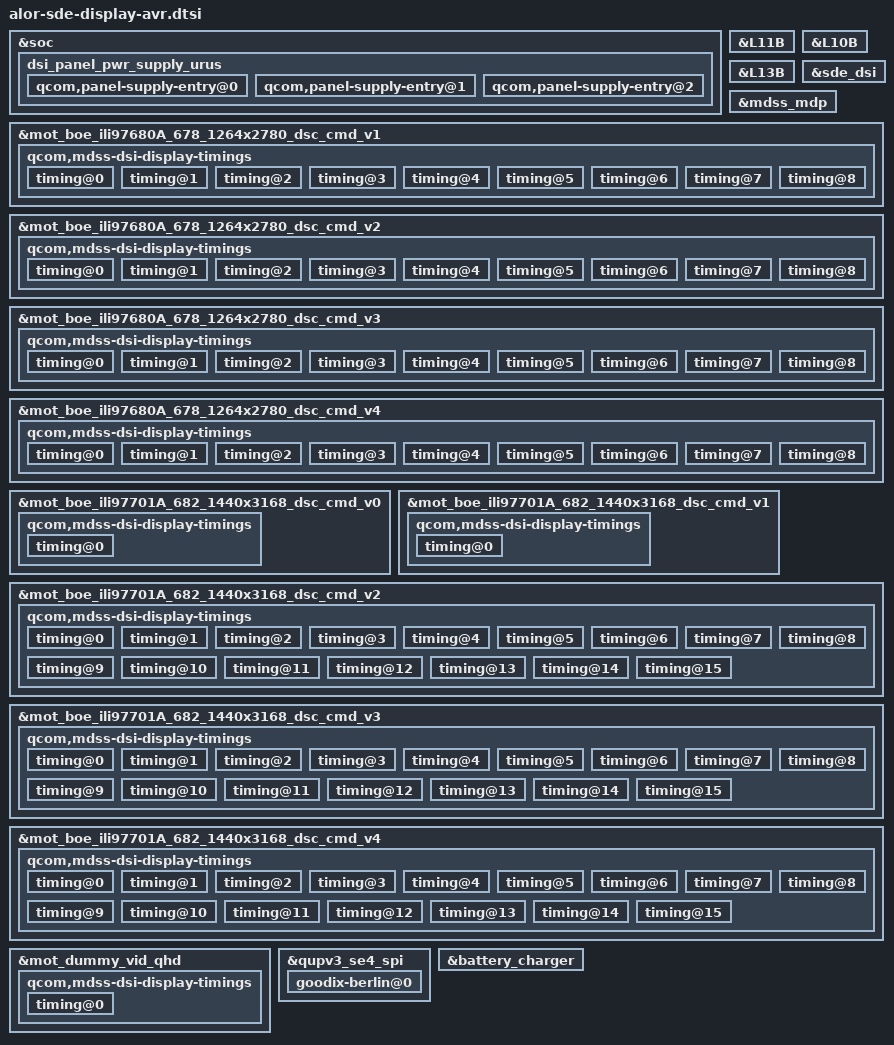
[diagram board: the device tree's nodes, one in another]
// SPDX-License-Identifier: BSD-3-Clause
/*
 * Copyright (c) Qualcomm Technologies, Inc. and/or its subsidiaries.
 */

#include "alor-sde-display.dtsi"
#include "dsi-panel-mot-dummy-qhd-video-dsi1.dtsi"
#include "dsi-panel-mot-boe-ili97680A-678-1264x2780-dsc-cmd-common_vantage_v1.dtsi"
#include "dsi-panel-mot-boe-ili97680A-678-1264x2780-dsc-cmd-common_vantage_v2.dtsi"
#include "dsi-panel-mot-boe-ili97680A-678-1264x2780-dsc-cmd-common_vantage_v3.dtsi"
#include "dsi-panel-mot-boe-ili97680A-678-1264x2780-dsc-cmd-common_vantage_v4.dtsi"
#include "dsi-panel-mot-boe-ili97701A-682-1440x3168-dsc-cmd-common_v0.dtsi"
#include "dsi-panel-mot-boe-ili97701A-682-1440x3168-dsc-cmd-common_v1.dtsi"
#include "dsi-panel-mot-boe-ili97701A-682-1440x3168-dsc-cmd-common_v2.dtsi"
#include "dsi-panel-mot-boe-ili97701A-682-1440x3168-dsc-cmd-common_v3.dtsi"
#include "dsi-panel-mot-boe-ili97701A-682-1440x3168-dsc-cmd-common_v4.dtsi"
&soc {
	dsi_panel_pwr_supply_urus: dsi_panel_pwr_supply_urus {
		#address-cells = <1>;
		#size-cells = <0>;

	qcom,panel-supply-entry@0 {
		reg = <0>;
		qcom,supply-name = "vddio";
		qcom,supply-min-voltage = <1850000>;
		qcom,supply-max-voltage = <1850000>;
		qcom,supply-enable-load = <300000>;
		qcom,supply-disable-load = <100>;
		qcom,supply-pre-on-sleep = <0>;
		qcom,supply-post-on-sleep = <1>;
		qcom,supply-pre-off-sleep = <0>;
		qcom,supply-post-off-sleep = <0>;
        };
	qcom,panel-supply-entry@1 {
		reg = <1>;
		qcom,supply-name = "vdd";
		qcom,supply-min-voltage = <1060000>;
		qcom,supply-max-voltage = <1060000>;
		qcom,supply-enable-load = <300000>;
		qcom,supply-disable-load = <100>;
		qcom,supply-pre-on-sleep = <0>;
		qcom,supply-post-on-sleep = <1>;
		qcom,supply-pre-off-sleep = <0>;
		qcom,supply-post-off-sleep = <1>;
        };

        qcom,panel-supply-entry@2 {
		reg = <2>;
		qcom,supply-name = "vci";
		qcom,supply-min-voltage = <3000000>;
		qcom,supply-max-voltage = <3000000>;
		qcom,supply-enable-load = <3000000>;
		qcom,supply-disable-load = <0>;
		qcom,supply-pre-on-sleep = <0>;
		qcom,supply-post-on-sleep = <0>;
		qcom,supply-pre-off-sleep = <1>;
		qcom,supply-post-off-sleep = <1>;
        };
	};
};
&L11B {
       regulator-min-microvolt = <1060000>;
       regulator-max-microvolt = <1060000>;
       qcom,init-voltage = <1060000>;
};
&L10B {
       regulator-min-microvolt = <1850000>;
       regulator-max-microvolt = <1850000>;
       qcom,init-voltage = <1850000>;
};
&L13B {
       regulator-min-microvolt = <3000000>;
       regulator-max-microvolt = <3000000>;
       qcom,init-voltage = <3000000>;
};

&sde_dsi {
	pinctrl-names = "panel_active", "panel_suspend";
	pinctrl-0 = <&sde_dsi_active &sde_te_active>;
	pinctrl-1 = <&sde_dsi_suspend &sde_te_suspend>;
	/delete-property/ pinctrl-2;
};

&mdss_mdp {
	connectors = <&sde_dsi &sde_dsi1 &smmu_sde_unsec &smmu_sde_sec &sde_wb0 &sde_wb1 &sde_cesta>;
};
&mot_boe_ili97680A_678_1264x2780_dsc_cmd_v1 {
	qcom,dsi-select-clocks = "pll_byte_clk1", "pll_dsi_clk1";
	qcom,dsi-ctrl-num = <1>;
	qcom,dsi-phy-num = <1>;
	qcom,panel-supply-entries = <&dsi_panel_pwr_supply_urus>;
	qcom,mdss-dsi-no-panel-on-read-support;
	qcom,mdss-dsi-bl-pmic-control-type = "bl_ctrl_dcs";
	qcom,mdss-dsi-bl-min-level = <420>;
	qcom,mdss-dsi-bl-max-level = <16180>;
	qcom,mdss-dsi-bl-default-level = <7001>;
	qcom,mdss-brightness-max-level = <16180>;
	qcom,platform-reset-gpio = <&tlmm 146 0>;
	qcom,bl-dsc-cmd-state = "dsi_hs_mode";
	qcom,mdss-dsi-bl-inverted-dbv;
	qcom,mdss-dsi-bl-is-exponent;
	qcom,mdss-disable-cesta-hw-sleep;

	qcom,mdss-dsi-panel-status-check-mode = "reg_read";
	qcom,mdss-dsi-panel-status-command = [06 01 00 01 00 00 01 0a];
	qcom,mdss-dsi-panel-status-command-state = "dsi_lp_mode";
	qcom,mdss-dsi-panel-status-value = <0x9c>;
	qcom,mdss-dsi-panel-status-read-length = <1>;
	qcom,esd-check-enabled;
	qcom,cellid-read-enabled;
	qcom,mdss-dsi-panel-cellid-send-command-enabled;
	qcom,mdss-dsi-panel-cellid-send-command = [
		39 00 00 00 00 00 04 FF 5A A5 1D];
	qcom,mdss-dsi-panel-cellid-read-length = <23>;
	qcom,mdss-dsi-panel-cellid-offset = <0>;
	qcom,mdss-dsi-panel-cellid-command = [
		06 01 00 01 00 00 01 80];
	qcom,mdss-dsi-panel-cellid-send-back-command = [
		39 00 00 00 00 00 04 FF 5A A5 00];

	qcom,mdss-dsi-panel-hdr-enabled;
	qcom,mdss-dsi-panel-hdr-color-primaries = <15600 16450 34000
	        16000 13250 34500 7500 3000>;
	qcom,mdss-dsi-panel-peak-brightness = <15000000>;
	qcom,mdss-dsi-panel-blackness-level = <1>;

	qcom,mdss-dsi-hbm-off-command = [
		39 00 00 40 00 00 04 FF 5A A5 1F
		39 00 00 40 00 00 1f C3 FA FF FF E9 E9 AA E9 E9 E9 E9 AA E9 E9 E9 E9 AA E9 E9 E9 E9 AA E9 E9 E9 E9 AA E9 E9 E9 E9
		39 00 00 40 00 00 04 FF 5A A5 1E
		39 00 00 40 00 00 02 9A 13
		39 00 00 40 00 00 02 80 89
		39 00 00 40 00 00 04 FF 5A A5 00
		39 00 00 00 00 00 03 51 2C 50
	];
	qcom,mdss-dsi-hbm-off-command-state = "dsi_hs_mode";
	qcom,mdss-dsi-hbm-on-command = [
		39 00 00 40 00 00 04 FF 5A A5 1F
		39 00 00 40 00 00 1f C3 FA FF FF E9 E9 AA E9 E9 E9 E9 AA E9 E9 E9 E9 AA E9 E9 E9 E9 AA E9 E9 E9 E9 AA E9 E9 E9 E9
		39 00 00 40 00 00 04 FF 5A A5 1E
		39 00 00 40 00 00 02 9A 13
		39 00 00 40 00 00 02 80 A9
		39 00 00 40 00 00 04 FF 5A A5 00
		39 00 00 00 00 00 03 51 3F FC
	];
	qcom,mdss-dsi-hbm-on-command-state = "dsi_hs_mode";

	qcom,apl-enabled;
	qcom,mdss-dsi-panel-APL-THRESHOLD-BL = <16000>;
	qcom,mdss-dsi-panel-APL-FUNC-ID = <0>;
	qcom,mdss-dsi-panel-apl-on-command = [
		39 00 00 40 00 00 04 FF 5A A5 1F
		39 00 00 40 00 00 1f C3 FA FF FF E9 E9 AA E9 E9 E9 E9 AA E9 E9 E9 E9 AA E9 E9 E9 E9 AA E9 E9 E9 E9 AA E9 E9 E9 E9
		39 00 00 40 00 00 04 FF 5A A5 1E
		39 00 00 40 00 00 02 9A 13
		39 00 00 40 00 00 02 80 A9
		39 00 00 00 00 00 04 FF 5A A5 00];
	qcom,mdss-dsi-panel-apl-off-command = [
		39 00 00 40 00 00 04 FF 5A A5 1F
		39 00 00 40 00 00 1f C3 FA FF FF E9 E9 AA E9 E9 E9 E9 AA E9 E9 E9 E9 AA E9 E9 E9 E9 AA E9 E9 E9 E9 AA E9 E9 E9 E9
		39 00 00 40 00 00 04 FF 5A A5 1E
		39 00 00 40 00 00 02 9A 13
		39 00 00 40 00 00 02 80 89
		39 00 00 00 00 00 04 FF 5A A5 00];

	//qcom,ulps-enabled;
	//qcom,qsync-enable;
	qcom,mdss-dsi-qsync-min-refresh-rate = <1>;
	qcom,mdss-dsi-display-timings {
		timing@0 { //120
			qcom,framerate-group-no-duplicated;
			qcom,framerate-group-120hz-based;
			qcom,mdss-dsi-panel-clockrate = <1079000000>;
			qcom,display-topology = <2 2 1>;
			qcom,default-topology-index = <0>;
			qcom,mdss-dsi-panel-phy-timings = [00 24 09 09 1A 18 09
							09 09 02 04 00 1E 0E];
		};
		timing@1 {//165hz
			qcom,framerate-group-no-duplicated;
			qcom,mdss-dsi-panel-clockrate = <1483000000>;
			qcom,display-topology = <2 2 1>;
			qcom,default-topology-index = <0>;
			qcom,mdss-dsi-panel-phy-timings = [00 2F 0D 0D 1E 1C 0C
							0D 0C 02 04 00 27 11];
		};
		timing@2 {//90hz
			qcom,framerate-group-no-duplicated;
			qcom,framerate-group-90hz-based;
			qcom,mdss-dsi-panel-clockrate = <809000000>;
			qcom,display-topology = <2 2 1>;
			qcom,default-topology-index = <0>;
			qcom,mdss-dsi-panel-phy-timings = [00 1C 07 07 17 21 07
							07 08 02 04 00 18 0C];
		};
		timing@3 {//60hz
			qcom,framerate-group-no-duplicated;
			qcom,framerate-group-120hz-based;
			qcom,mdss-dsi-panel-clockrate = <539000000>;
			qcom,display-topology = <2 2 1>;
			qcom,default-topology-index = <0>;
			qcom,mdss-dsi-panel-phy-timings = [00 14 05 05 13 1F 05
							05 06 02 04 00 12 0A];
		};
		timing@4 { //30
			qcom,framerate-group-no-duplicated;
			qcom,framerate-group-120hz-based;
			qcom,mdss-dsi-panel-clockrate = <1079000000>;
			qcom,display-topology = <2 2 1>;
			qcom,default-topology-index = <0>;
			qcom,mdss-dsi-panel-phy-timings = [00 24 09 09 1A 18 09
							09 09 02 04 00 1E 0E];
		};
		timing@5 { //24
			qcom,framerate-group-no-duplicated;
			qcom,framerate-group-120hz-based;
			qcom,mdss-dsi-panel-clockrate = <1079000000>;
			qcom,display-topology = <2 2 1>;
			qcom,default-topology-index = <0>;
			qcom,mdss-dsi-panel-phy-timings = [00 24 09 09 1A 18 09
							09 09 02 04 00 1E 0E];
		};
		timing@6 { //10 independent
			qcom,framerate-group-special-idle-10hz;
			qcom,mdss-dsi-panel-clockrate = <1079000000>;
			qcom,display-topology = <2 2 1>;
			qcom,default-topology-index = <0>;
			qcom,mdss-dsi-panel-phy-timings = [00 24 09 09 1A 18 09
							09 09 02 04 00 1E 0E];
		};
		timing@7 { //1 independent
			qcom,framerate-group-special-idle-1hz;
			qcom,mdss-dsi-panel-clockrate = <1079000000>;
			qcom,display-topology = <2 2 1>;
			qcom,default-topology-index = <0>;
			qcom,mdss-dsi-panel-phy-timings = [00 24 09 09 1A 18 09
							09 09 02 04 00 1E 0E];
		};
		timing@8 { //120 qsync
			qcom,framerate-group-VRR-refreshrate-120hz;
			qcom,display-topology = <2 2 1>;
			qcom,default-topology-index = <0>;
			qcom,mdss-dsi-panel-phy-timings = [00 24 09 09 1A 18 09
							09 09 02 04 00 1E 0E];
		};
	};
};
&mot_boe_ili97680A_678_1264x2780_dsc_cmd_v2 {
	qcom,dsi-select-clocks = "pll_byte_clk1", "pll_dsi_clk1";
	qcom,dsi-ctrl-num = <1>;
	qcom,dsi-phy-num = <1>;
	qcom,panel-supply-entries = <&dsi_panel_pwr_supply_urus>;
	qcom,mdss-dsi-no-panel-on-read-support;
	qcom,mdss-dsi-bl-pmic-control-type = "bl_ctrl_dcs";
	qcom,mdss-dsi-bl-min-level = <420>;
	qcom,mdss-dsi-bl-max-level = <16180>;
	qcom,mdss-dsi-bl-default-level = <7001>;
	qcom,mdss-brightness-max-level = <16180>;
	qcom,platform-reset-gpio = <&tlmm 146 0>;
	qcom,platform-sec-reset-gpio = <&tlmm 146 0>;
	qcom,bl-dsc-cmd-state = "dsi_hs_mode";
	qcom,mdss-dsi-bl-inverted-dbv;
	qcom,mdss-dsi-bl-is-exponent;
	qcom,mdss-disable-cesta-hw-sleep;

	qcom,mdss-dsi-panel-status-check-mode = "reg_read";
	qcom,mdss-dsi-panel-status-command = [06 01 00 01 00 00 01 0a];
	qcom,mdss-dsi-panel-status-command-state = "dsi_lp_mode";
	qcom,mdss-dsi-panel-status-value = <0x9C>;
	qcom,mdss-dsi-panel-status-read-length = <1>;
	qcom,esd-check-enabled;
	qcom,cellid-read-enabled;
	qcom,mdss-dsi-panel-cellid-send-command-enabled;
	qcom,mdss-dsi-panel-cellid-send-command = [
		39 00 00 00 00 00 04 FF 5A A5 1D];
	qcom,mdss-dsi-panel-cellid-read-length = <23>;
	qcom,mdss-dsi-panel-cellid-offset = <0>;
	qcom,mdss-dsi-panel-cellid-command = [
		06 01 00 01 00 00 01 80];
	qcom,mdss-dsi-panel-cellid-send-back-command = [
		39 00 00 00 00 00 04 FF 5A A5 00];

	qcom,mdss-dsi-panel-hdr-enabled;
	qcom,mdss-dsi-panel-hdr-color-primaries = <15600 16450 34000
	        16000 13250 34500 7500 3000>;
	qcom,mdss-dsi-panel-peak-brightness = <15000000>;
	qcom,mdss-dsi-panel-blackness-level = <1>;

	qcom,mdss-dsi-hbm-off-command = [
		39 00 00 40 00 00 04 FF 5A A5 1F
		39 00 00 40 00 00 1f C3 FA FF FF E9 E9 AA E9 E9 E9 E9 AA E9 E9 E9 E9 AA E9 E9 E9 E9 AA E9 E9 E9 E9 AA E9 E9 E9 E9
		39 00 00 40 00 00 04 FF 5A A5 1E
		39 00 00 40 00 00 02 9A 13
		39 00 00 40 00 00 02 80 89
		39 00 00 40 00 00 04 FF 5A A5 00
		39 00 00 00 00 00 03 51 2C 50
	];
	qcom,mdss-dsi-hbm-off-command-state = "dsi_hs_mode";
	qcom,mdss-dsi-hbm-on-command = [
		39 00 00 40 00 00 04 FF 5A A5 1F
		39 00 00 40 00 00 1f C3 FA FF FF E9 E9 AA E9 E9 E9 E9 AA E9 E9 E9 E9 AA E9 E9 E9 E9 AA E9 E9 E9 E9 AA E9 E9 E9 E9
		39 00 00 40 00 00 04 FF 5A A5 1E
		39 00 00 40 00 00 02 9A 13
		39 00 00 40 00 00 02 80 A9
		39 00 00 40 00 00 04 FF 5A A5 00
		39 00 00 00 00 00 03 51 3F FC
	];
	qcom,mdss-dsi-hbm-on-command-state = "dsi_hs_mode";

	qcom,apl-enabled;
	qcom,mdss-dsi-panel-APL-THRESHOLD-BL = <16000>;
	qcom,mdss-dsi-panel-APL-FUNC-ID = <0>;
	qcom,mdss-dsi-panel-apl-on-command = [
		39 00 00 40 00 00 04 FF 5A A5 1F
		39 00 00 40 00 00 1f C3 FA FF FF E9 E9 AA E9 E9 E9 E9 AA E9 E9 E9 E9 AA E9 E9 E9 E9 AA E9 E9 E9 E9 AA E9 E9 E9 E9
		39 00 00 40 00 00 04 FF 5A A5 1E
		39 00 00 40 00 00 02 9A 13
		39 00 00 40 00 00 02 80 A9
		39 00 00 00 00 00 04 FF 5A A5 00];
	qcom,mdss-dsi-panel-apl-off-command = [
		39 00 00 40 00 00 04 FF 5A A5 1F
		39 00 00 40 00 00 1f C3 FA FF FF E9 E9 AA E9 E9 E9 E9 AA E9 E9 E9 E9 AA E9 E9 E9 E9 AA E9 E9 E9 E9 AA E9 E9 E9 E9
		39 00 00 40 00 00 04 FF 5A A5 1E
		39 00 00 40 00 00 02 9A 13
		39 00 00 40 00 00 02 80 89
		39 00 00 00 00 00 04 FF 5A A5 00];

	//qcom,ulps-enabled;
	//qcom,qsync-enable;
	qcom,mdss-dsi-qsync-min-refresh-rate = <1>;
	qcom,mdss-dsi-display-timings {
		timing@0 { //120
			qcom,framerate-group-no-duplicated;
			qcom,framerate-group-120hz-based;
			qcom,mdss-dsi-panel-clockrate = <1079000000>;
			qcom,display-topology = <2 2 1>;
			qcom,default-topology-index = <0>;
			qcom,mdss-dsi-panel-phy-timings = [00 24 09 09 1A 18 09
							09 09 02 04 00 1E 0E];
		};
		timing@1 {//165hz
			qcom,framerate-group-no-duplicated;
			qcom,mdss-dsi-panel-clockrate = <1483000000>;
			qcom,display-topology = <2 2 1>;
			qcom,default-topology-index = <0>;
			qcom,mdss-dsi-panel-phy-timings = [00 2F 0D 0D 1E 1C 0C
							0D 0C 02 04 00 27 11];
		};
		timing@2 {//90hz
			qcom,framerate-group-no-duplicated;
			qcom,framerate-group-90hz-based;
			qcom,mdss-dsi-panel-clockrate = <809000000>;
			qcom,display-topology = <2 2 1>;
			qcom,default-topology-index = <0>;
			qcom,mdss-dsi-panel-phy-timings = [00 1C 07 07 17 21 07
							07 08 02 04 00 18 0C];
		};
		timing@3 {//60hz
			qcom,framerate-group-no-duplicated;
			qcom,framerate-group-120hz-based;
			qcom,mdss-dsi-panel-clockrate = <539000000>;
			qcom,display-topology = <2 2 1>;
			qcom,default-topology-index = <0>;
			qcom,mdss-dsi-panel-phy-timings = [00 14 05 05 13 1F 05
							05 06 02 04 00 12 0A];
		};
		timing@4 { //30
			qcom,framerate-group-no-duplicated;
			qcom,framerate-group-120hz-based;
			qcom,mdss-dsi-panel-clockrate = <1079000000>;
			qcom,display-topology = <2 2 1>;
			qcom,default-topology-index = <0>;
			qcom,mdss-dsi-panel-phy-timings = [00 24 09 09 1A 18 09
							09 09 02 04 00 1E 0E];
		};
		timing@5 { //24
			qcom,framerate-group-no-duplicated;
			qcom,framerate-group-120hz-based;
			qcom,mdss-dsi-panel-clockrate = <1079000000>;
			qcom,display-topology = <2 2 1>;
			qcom,default-topology-index = <0>;
			qcom,mdss-dsi-panel-phy-timings = [00 24 09 09 1A 18 09
							09 09 02 04 00 1E 0E];
		};
		timing@6 { //10 independent
			qcom,framerate-group-special-idle-10hz;
			qcom,mdss-dsi-panel-clockrate = <1079000000>;
			qcom,display-topology = <2 2 1>;
			qcom,default-topology-index = <0>;
			qcom,mdss-dsi-panel-phy-timings = [00 24 09 09 1A 18 09
							09 09 02 04 00 1E 0E];
		};
		timing@7 { //1 independent
			qcom,framerate-group-special-idle-1hz;
			qcom,mdss-dsi-panel-clockrate = <1079000000>;
			qcom,display-topology = <2 2 1>;
			qcom,default-topology-index = <0>;
			qcom,mdss-dsi-panel-phy-timings = [00 24 09 09 1A 18 09
							09 09 02 04 00 1E 0E];
		};
		timing@8 { //120 qsync
			qcom,framerate-group-VRR-refreshrate-120hz;
			qcom,display-topology = <2 2 1>;
			qcom,default-topology-index = <0>;
			qcom,mdss-dsi-panel-phy-timings = [00 24 09 09 1A 18 09
							09 09 02 04 00 1E 0E];
		};
	};
};
&mot_boe_ili97680A_678_1264x2780_dsc_cmd_v3 {
	qcom,dsi-select-clocks = "pll_byte_clk1", "pll_dsi_clk1";
	qcom,dsi-ctrl-num = <1>;
	qcom,dsi-phy-num = <1>;
	qcom,panel-supply-entries = <&dsi_panel_pwr_supply_urus>;
	qcom,mdss-dsi-no-panel-on-read-support;
	qcom,mdss-dsi-bl-pmic-control-type = "bl_ctrl_dcs";
	qcom,mdss-dsi-bl-min-level = <420>;
	qcom,mdss-dsi-bl-max-level = <16180>;
	qcom,mdss-dsi-bl-default-level = <7001>;
	qcom,mdss-brightness-max-level = <16180>;
	qcom,platform-reset-gpio = <&tlmm 146 0>;
	qcom,bl-dsc-cmd-state = "dsi_hs_mode";
	qcom,mdss-dsi-bl-inverted-dbv;
	qcom,mdss-dsi-bl-is-exponent;
	qcom,mdss-disable-cesta-hw-sleep;

	qcom,mdss-dsi-panel-status-check-mode = "reg_read";
	qcom,mdss-dsi-panel-status-command = [06 01 00 01 00 00 01 0a];
	qcom,mdss-dsi-panel-status-command-state = "dsi_lp_mode";
	qcom,mdss-dsi-panel-status-value = <0x9c>;
	qcom,mdss-dsi-panel-status-read-length = <1>;
	qcom,esd-check-enabled;
	qcom,cellid-read-enabled;
	qcom,mdss-dsi-panel-cellid-send-command-enabled;
	qcom,mdss-dsi-panel-cellid-send-command = [
		39 00 00 00 00 00 04 FF 5A A5 1D];
	qcom,mdss-dsi-panel-cellid-read-length = <23>;
	qcom,mdss-dsi-panel-cellid-offset = <0>;
	qcom,mdss-dsi-panel-cellid-command = [
		06 01 00 01 00 00 01 80];
	qcom,mdss-dsi-panel-cellid-send-back-command = [
		39 00 00 00 00 00 04 FF 5A A5 00];

	qcom,mdss-dsi-panel-hdr-enabled;
	qcom,mdss-dsi-panel-hdr-color-primaries = <15600 16450 34000
	        16000 13250 34500 7500 3000>;
	qcom,mdss-dsi-panel-peak-brightness = <15000000>;
	qcom,mdss-dsi-panel-blackness-level = <1>;

	qcom,mdss-dsi-hbm-off-command = [
		39 00 00 40 00 00 04 FF 5A A5 1E
		39 00 00 40 00 00 02 80 89
		39 00 00 40 00 00 04 FF 5A A5 00
		39 00 00 00 00 00 03 51 2C 50
	];
	qcom,mdss-dsi-hbm-off-command-state = "dsi_hs_mode";
	qcom,mdss-dsi-hbm-on-command = [
		39 00 00 40 00 00 04 FF 5A A5 1F
		39 00 00 40 00 00 1f C3 FF FF EF A0 FF AA E9 E9 E9 E9 AA E9 E9 E9 E9 AA E9 E9 E9 E9 AA E9 E9 E9 E9 AA E9 E9 E9 E9
		39 00 00 40 00 00 04 FF 5A A5 1E
		39 00 00 40 00 00 02 9A 13
		39 00 00 40 00 00 02 80 A9
		39 00 00 40 00 00 04 FF 5A A5 00
		39 00 00 00 00 00 03 51 3F FC
	];
	qcom,mdss-dsi-hbm-on-command-state = "dsi_hs_mode";

	qcom,apl-enabled;
	qcom,mdss-dsi-panel-APL-THRESHOLD-BL = <16000>;
	qcom,mdss-dsi-panel-APL-FUNC-ID = <0>;
	qcom,mdss-dsi-panel-apl-on-command = [
		39 00 00 40 00 00 04 FF 5A A5 1F
		39 00 00 40 00 00 1f C3 FF FF EF A0 FF AA E9 E9 E9 E9 AA E9 E9 E9 E9 AA E9 E9 E9 E9 AA E9 E9 E9 E9 AA E9 E9 E9 E9
		39 00 00 40 00 00 04 FF 5A A5 1E
		39 00 00 40 00 00 02 9A 13
		39 00 00 40 00 00 02 80 A9
		39 00 00 00 00 00 04 FF 5A A5 00];
	qcom,mdss-dsi-panel-apl-off-command = [
		39 00 00 40 00 00 04 FF 5A A5 1E
		39 00 00 40 00 00 02 80 89
		39 00 00 00 00 00 04 FF 5A A5 00];

	qcom,odc-enabled;
	qcom,mdss-dsi-panel-ODC-THRESHOLD-BL = <1920>;
	qcom,mdss-dsi-panel-odc-on-command = [
		39 00 00 40 00 00 04 FF 5A A5 49
		39 00 00 40 00 00 02 E0 01
		39 00 00 00 00 00 04 FF 5A A5 00];
	qcom,mdss-dsi-panel-odc-off-command = [
		39 00 00 40 00 00 04 FF 5A A5 49
		39 00 00 40 00 00 02 E0 00
		39 00 00 00 00 00 04 FF 5A A5 00];

	qcom,switch-timing-delay-enabled;
	qcom,switch-orig-timing-list = <165>;
	qcom,switch-active-timing-list = <60>;
	qcom,switch-delay-list = <17>;

	//qcom,ulps-enabled;
	//qcom,qsync-enable;
	qcom,mdss-dsi-qsync-min-refresh-rate = <1>;
	qcom,mdss-dsi-display-timings {
		timing@0 { //120
			qcom,framerate-group-no-duplicated;
			qcom,framerate-group-120hz-based;
			qcom,mdss-dsi-panel-clockrate = <1079000000>;
			qcom,display-topology = <2 2 1>;
			qcom,default-topology-index = <0>;
			qcom,mdss-dsi-panel-phy-timings = [00 24 09 09 1A 18 09
							09 09 02 04 00 1E 0E];
		};
		timing@1 {//165hz
			qcom,framerate-group-no-duplicated;
			qcom,mdss-dsi-panel-clockrate = <1483000000>;
			qcom,display-topology = <2 2 1>;
			qcom,default-topology-index = <0>;
			qcom,mdss-dsi-panel-phy-timings = [00 2F 0D 0D 1E 1C 0C
							0D 0C 02 04 00 27 11];
		};
		timing@2 {//90hz
			qcom,framerate-group-no-duplicated;
			qcom,framerate-group-90hz-based;
			qcom,mdss-dsi-panel-clockrate = <809000000>;
			qcom,display-topology = <2 2 1>;
			qcom,default-topology-index = <0>;
			qcom,mdss-dsi-panel-phy-timings = [00 1C 07 07 17 21 07
							07 08 02 04 00 18 0C];
		};
		timing@3 {//60hz
			qcom,framerate-group-no-duplicated;
			qcom,framerate-group-120hz-based;
			qcom,mdss-dsi-panel-clockrate = <539000000>;
			qcom,display-topology = <2 2 1>;
			qcom,default-topology-index = <0>;
			qcom,mdss-dsi-panel-phy-timings = [00 14 05 05 13 1F 05
							05 06 02 04 00 12 0A];
		};
		timing@4 { //30
			qcom,framerate-group-no-duplicated;
			qcom,framerate-group-120hz-based;
			qcom,mdss-dsi-panel-clockrate = <1079000000>;
			qcom,display-topology = <2 2 1>;
			qcom,default-topology-index = <0>;
			qcom,mdss-dsi-panel-phy-timings = [00 24 09 09 1A 18 09
							09 09 02 04 00 1E 0E];
		};
		timing@5 { //24
			qcom,framerate-group-no-duplicated;
			qcom,framerate-group-120hz-based;
			qcom,mdss-dsi-panel-clockrate = <1079000000>;
			qcom,display-topology = <2 2 1>;
			qcom,default-topology-index = <0>;
			qcom,mdss-dsi-panel-phy-timings = [00 24 09 09 1A 18 09
							09 09 02 04 00 1E 0E];
		};
		timing@6 { //10 independent
			qcom,framerate-group-special-idle-10hz;
			qcom,mdss-dsi-panel-clockrate = <1079000000>;
			qcom,display-topology = <2 2 1>;
			qcom,default-topology-index = <0>;
			qcom,mdss-dsi-panel-phy-timings = [00 24 09 09 1A 18 09
							09 09 02 04 00 1E 0E];
		};
		timing@7 { //1 independent
			qcom,framerate-group-special-idle-1hz;
			qcom,mdss-dsi-panel-clockrate = <1079000000>;
			qcom,display-topology = <2 2 1>;
			qcom,default-topology-index = <0>;
			qcom,mdss-dsi-panel-phy-timings = [00 24 09 09 1A 18 09
							09 09 02 04 00 1E 0E];
		};
		timing@8 { //120 qsync
			qcom,framerate-group-VRR-refreshrate-120hz;
			qcom,display-topology = <2 2 1>;
			qcom,default-topology-index = <0>;
			qcom,mdss-dsi-panel-phy-timings = [00 24 09 09 1A 18 09
							09 09 02 04 00 1E 0E];
		};
	};
};

&mot_boe_ili97680A_678_1264x2780_dsc_cmd_v4 {
	qcom,dsi-select-clocks = "pll_byte_clk1", "pll_dsi_clk1";
	qcom,dsi-ctrl-num = <1>;
	qcom,dsi-phy-num = <1>;
	qcom,panel-supply-entries = <&dsi_panel_pwr_supply_urus>;
	qcom,mdss-dsi-no-panel-on-read-support;
	qcom,mdss-dsi-bl-pmic-control-type = "bl_ctrl_dcs";
	qcom,mdss-dsi-bl-min-level = <420>;
	qcom,mdss-dsi-bl-max-level = <16180>;
	qcom,mdss-dsi-bl-default-level = <7001>;
	qcom,mdss-brightness-max-level = <16180>;
	qcom,platform-reset-gpio = <&tlmm 146 0>;
	qcom,bl-dsc-cmd-state = "dsi_hs_mode";
	qcom,mdss-dsi-bl-inverted-dbv;
	qcom,mdss-dsi-bl-is-exponent;
	qcom,mdss-disable-cesta-hw-sleep;

	qcom,mdss-dsi-panel-status-check-mode = "reg_read";
	qcom,mdss-dsi-panel-status-command = [06 01 00 01 00 00 01 0a];
	qcom,mdss-dsi-panel-status-command-state = "dsi_lp_mode";
	qcom,mdss-dsi-panel-status-value = <0x9c>;
	qcom,mdss-dsi-panel-status-read-length = <1>;
	qcom,esd-check-enabled;
	qcom,cellid-read-enabled;
	qcom,mdss-dsi-panel-cellid-send-command-enabled;
	qcom,mdss-dsi-panel-cellid-send-command = [
		39 00 00 00 00 00 04 FF 5A A5 1D];
	qcom,mdss-dsi-panel-cellid-read-length = <23>;
	qcom,mdss-dsi-panel-cellid-offset = <0>;
	qcom,mdss-dsi-panel-cellid-command = [
		06 01 00 01 00 00 01 80];
	qcom,mdss-dsi-panel-cellid-send-back-command = [
		39 00 00 00 00 00 04 FF 5A A5 00];

	qcom,mdss-dsi-panel-hdr-enabled;
	qcom,mdss-dsi-panel-hdr-color-primaries = <15600 16450 34000
	        16000 13250 34500 7500 3000>;
	qcom,mdss-dsi-panel-peak-brightness = <15000000>;
	qcom,mdss-dsi-panel-blackness-level = <1>;

	qcom,mdss-dsi-hbm-off-command = [
		39 00 00 40 00 00 04 FF 5A A5 1E
		39 00 00 40 00 00 02 80 89
		39 00 00 40 00 00 04 FF 5A A5 00
		39 00 00 00 00 00 03 51 2C 50
	];
	qcom,mdss-dsi-hbm-off-command-state = "dsi_hs_mode";
	qcom,mdss-dsi-hbm-on-command = [
		39 00 00 40 00 00 04 FF 5A A5 1F
		39 00 00 40 00 00 1f C3 FF FF EF A0 FF AA E9 E9 E9 E9 AA E9 E9 E9 E9 AA E9 E9 E9 E9 AA E9 E9 E9 E9 AA E9 E9 E9 E9
		39 00 00 40 00 00 04 FF 5A A5 1E
		39 00 00 40 00 00 02 9A 13
		39 00 00 40 00 00 02 80 A9
		39 00 00 40 00 00 04 FF 5A A5 00
		39 00 00 00 00 00 03 51 3F FC
	];
	qcom,mdss-dsi-hbm-on-command-state = "dsi_hs_mode";

	qcom,apl-enabled;
	qcom,mdss-dsi-panel-APL-THRESHOLD-BL = <16000>;
	qcom,mdss-dsi-panel-APL-FUNC-ID = <0>;
	qcom,mdss-dsi-panel-apl-on-command = [
		39 00 00 40 00 00 04 FF 5A A5 1F
		39 00 00 40 00 00 1f C3 FF FF EF A0 FF AA E9 E9 E9 E9 AA E9 E9 E9 E9 AA E9 E9 E9 E9 AA E9 E9 E9 E9 AA E9 E9 E9 E9
		39 00 00 40 00 00 04 FF 5A A5 1E
		39 00 00 40 00 00 02 9A 13
		39 00 00 40 00 00 02 80 A9
		39 00 00 00 00 00 04 FF 5A A5 00];
	qcom,mdss-dsi-panel-apl-off-command = [
		39 00 00 40 00 00 04 FF 5A A5 1E
		39 00 00 40 00 00 02 80 89
		39 00 00 00 00 00 04 FF 5A A5 00];

	qcom,odc-enabled;
	qcom,mdss-dsi-panel-ODC-THRESHOLD-BL = <1920>;
	qcom,mdss-dsi-panel-odc-on-command = [
		39 00 00 40 00 00 04 FF 5A A5 49
		39 00 00 40 00 00 02 E0 01
		39 00 00 00 00 00 04 FF 5A A5 00];
	qcom,mdss-dsi-panel-odc-off-command = [
		39 00 00 40 00 00 04 FF 5A A5 49
		39 00 00 40 00 00 02 E0 00
		39 00 00 00 00 00 04 FF 5A A5 00];

	qcom,switch-timing-delay-enabled;
	qcom,switch-orig-timing-list = <165>;
	qcom,switch-active-timing-list = <60>;
	qcom,switch-delay-list = <17>;

	//qcom,ulps-enabled;
	//qcom,qsync-enable;
	qcom,mdss-dsi-qsync-min-refresh-rate = <1>;
	qcom,mdss-dsi-display-timings {
		timing@0 { //120
			qcom,framerate-group-no-duplicated;
			qcom,framerate-group-120hz-based;
			qcom,mdss-dsi-panel-clockrate = <1079000000>;
			qcom,display-topology = <2 2 1>;
			qcom,default-topology-index = <0>;
			qcom,mdss-dsi-panel-phy-timings = [00 24 09 09 1A 18 09
							09 09 02 04 00 1E 0E];
		};
		timing@1 {//165hz
			qcom,framerate-group-no-duplicated;
			qcom,mdss-dsi-panel-clockrate = <1483000000>;
			qcom,display-topology = <2 2 1>;
			qcom,default-topology-index = <0>;
			qcom,mdss-dsi-panel-phy-timings = [00 2F 0D 0D 1E 1C 0C
							0D 0C 02 04 00 27 11];
		};
		timing@2 {//90hz
			qcom,framerate-group-no-duplicated;
			qcom,framerate-group-90hz-based;
			qcom,mdss-dsi-panel-clockrate = <809000000>;
			qcom,display-topology = <2 2 1>;
			qcom,default-topology-index = <0>;
			qcom,mdss-dsi-panel-phy-timings = [00 1C 07 07 17 21 07
							07 08 02 04 00 18 0C];
		};
		timing@3 {//60hz
			qcom,framerate-group-no-duplicated;
			qcom,framerate-group-120hz-based;
			qcom,mdss-dsi-panel-clockrate = <539000000>;
			qcom,display-topology = <2 2 1>;
			qcom,default-topology-index = <0>;
			qcom,mdss-dsi-panel-phy-timings = [00 14 05 05 13 1F 05
							05 06 02 04 00 12 0A];
		};
		timing@4 { //30
			qcom,framerate-group-no-duplicated;
			qcom,framerate-group-120hz-based;
			qcom,mdss-dsi-panel-clockrate = <1079000000>;
			qcom,display-topology = <2 2 1>;
			qcom,default-topology-index = <0>;
			qcom,mdss-dsi-panel-phy-timings = [00 24 09 09 1A 18 09
							09 09 02 04 00 1E 0E];
		};
		timing@5 { //24
			qcom,framerate-group-no-duplicated;
			qcom,framerate-group-120hz-based;
			qcom,mdss-dsi-panel-clockrate = <1079000000>;
			qcom,display-topology = <2 2 1>;
			qcom,default-topology-index = <0>;
			qcom,mdss-dsi-panel-phy-timings = [00 24 09 09 1A 18 09
							09 09 02 04 00 1E 0E];
		};
		timing@6 { //10 independent
			qcom,framerate-group-special-idle-10hz;
			qcom,mdss-dsi-panel-clockrate = <1079000000>;
			qcom,display-topology = <2 2 1>;
			qcom,default-topology-index = <0>;
			qcom,mdss-dsi-panel-phy-timings = [00 24 09 09 1A 18 09
							09 09 02 04 00 1E 0E];
		};
		timing@7 { //1 independent
			qcom,framerate-group-special-idle-1hz;
			qcom,mdss-dsi-panel-clockrate = <1079000000>;
			qcom,display-topology = <2 2 1>;
			qcom,default-topology-index = <0>;
			qcom,mdss-dsi-panel-phy-timings = [00 24 09 09 1A 18 09
							09 09 02 04 00 1E 0E];
		};
		timing@8 { //120 qsync
			qcom,framerate-group-VRR-refreshrate-120hz;
			qcom,display-topology = <2 2 1>;
			qcom,default-topology-index = <0>;
			qcom,mdss-dsi-panel-phy-timings = [00 24 09 09 1A 18 09
							09 09 02 04 00 1E 0E];
		};
	};
};

&mot_boe_ili97701A_682_1440x3168_dsc_cmd_v0 {
	qcom,dsi-select-clocks = "pll_byte_clk1", "pll_dsi_clk1";
	qcom,dsi-ctrl-num = <1>;
	qcom,dsi-phy-num = <1>;
	qcom,panel-supply-entries = <&dsi_panel_pwr_supply_urus>;
	qcom,mdss-dsi-no-panel-on-read-support;
	qcom,mdss-dsi-bl-pmic-control-type = "bl_ctrl_dcs";
	qcom,mdss-dsi-bl-min-level = <420>;
	qcom,mdss-dsi-bl-max-level = <16180>;
	qcom,mdss-dsi-bl-default-level = <7001>;
	qcom,mdss-brightness-max-level = <16180>;
	qcom,platform-reset-gpio = <&tlmm 146 0>;
	qcom,bl-dsc-cmd-state = "dsi_hs_mode";
	qcom,mdss-dsi-bl-inverted-dbv;
	qcom,mdss-dsi-bl-is-exponent;

	qcom,mdss-dsi-panel-status-check-mode = "reg_read";
	qcom,mdss-dsi-panel-status-command = [06 01 00 01 00 00 01 0a];
	qcom,mdss-dsi-panel-status-command-state = "dsi_lp_mode";
	qcom,mdss-dsi-panel-status-value = <0x9c>;
	qcom,mdss-dsi-panel-status-read-length = <1>;
	qcom,esd-check-enabled;
	qcom,cellid-read-enabled;
	qcom,mdss-dsi-panel-cellid-send-command-enabled;
	qcom,mdss-dsi-panel-cellid-send-command = [
		39 00 00 00 00 00 04 FF 5A A5 1D];
	qcom,mdss-dsi-panel-cellid-read-length = <23>;
	qcom,mdss-dsi-panel-cellid-offset = <0>;
	qcom,mdss-dsi-panel-cellid-command = [
		06 01 00 01 00 00 01 80];
	qcom,mdss-dsi-panel-cellid-send-back-command = [
		39 00 00 00 00 00 04 FF 5A A5 00];

	qcom,mdss-dsi-panel-hdr-enabled;
	qcom,mdss-dsi-panel-hdr-color-primaries = <15600 16450 34000
	        16000 13250 34500 7500 3000>;
	qcom,mdss-dsi-panel-peak-brightness = <15000000>;
	qcom,mdss-dsi-panel-blackness-level = <1>;

	//qcom,ulps-enabled;
	qcom,mdss-dsi-display-timings {
		timing@0 { //120
			qcom,framerate-group-no-duplicated;
			qcom,framerate-group-120hz-based;
			qcom,mdss-dsi-panel-clockrate = <1234000000>;
			qcom,display-topology = <2 2 1>;
			qcom,default-topology-index = <0>;
			qcom,mdss-dsi-panel-phy-timings = [00 29 0A 0B 1B 1A 0A
							0B 0A 02 04 00 21 10];
		};
	};
};

&mot_boe_ili97701A_682_1440x3168_dsc_cmd_v1 {
	qcom,dsi-select-clocks = "pll_byte_clk1", "pll_dsi_clk1";
	qcom,dsi-ctrl-num = <1>;
	qcom,dsi-phy-num = <1>;
	qcom,panel-supply-entries = <&dsi_panel_pwr_supply_urus>;
	qcom,mdss-dsi-no-panel-on-read-support;
	qcom,mdss-dsi-bl-pmic-control-type = "bl_ctrl_dcs";
	qcom,mdss-dsi-bl-min-level = <420>;
	qcom,mdss-dsi-bl-max-level = <16180>;
	qcom,mdss-dsi-bl-default-level = <7001>;
	qcom,mdss-brightness-max-level = <16180>;
	qcom,platform-reset-gpio = <&tlmm 146 0>;
	qcom,bl-dsc-cmd-state = "dsi_hs_mode";
	qcom,mdss-dsi-bl-inverted-dbv;
	qcom,mdss-dsi-bl-is-exponent;

	qcom,mdss-dsi-panel-status-check-mode = "reg_read";
	qcom,mdss-dsi-panel-status-command = [06 01 00 01 00 00 01 0a];
	qcom,mdss-dsi-panel-status-command-state = "dsi_lp_mode";
	qcom,mdss-dsi-panel-status-value = <0x9c>;
	qcom,mdss-dsi-panel-status-read-length = <1>;
	qcom,esd-check-enabled;
	qcom,cellid-read-enabled;
	qcom,mdss-dsi-panel-cellid-send-command-enabled;
	qcom,mdss-dsi-panel-cellid-send-command = [
		39 00 00 00 00 00 04 FF 5A A5 1D];
	qcom,mdss-dsi-panel-cellid-read-length = <23>;
	qcom,mdss-dsi-panel-cellid-offset = <0>;
	qcom,mdss-dsi-panel-cellid-command = [
		06 01 00 01 00 00 01 80];
	qcom,mdss-dsi-panel-cellid-send-back-command = [
		39 00 00 00 00 00 04 FF 5A A5 00];

	qcom,mdss-dsi-panel-hdr-enabled;
	qcom,mdss-dsi-panel-hdr-color-primaries = <15600 16450 34000
	        16000 13250 34500 7500 3000>;
	qcom,mdss-dsi-panel-peak-brightness = <15000000>;
	qcom,mdss-dsi-panel-blackness-level = <1>;

	//qcom,ulps-enabled;
	qcom,mdss-dsi-display-timings {
		timing@0 { //120
			qcom,framerate-group-no-duplicated;
			qcom,framerate-group-120hz-based;
			qcom,mdss-dsi-panel-clockrate = <1234000000>;
			qcom,display-topology = <2 2 1>;
			qcom,default-topology-index = <0>;
			qcom,mdss-dsi-panel-phy-timings = [00 29 0A 0B 1B 1A 0A
							0B 0A 02 04 00 21 10];
		};
	};
};

&mot_boe_ili97701A_682_1440x3168_dsc_cmd_v2 {
	qcom,dsi-select-clocks = "pll_byte_clk1", "pll_dsi_clk1";
	qcom,dsi-ctrl-num = <1>;
	qcom,dsi-phy-num = <1>;
	qcom,panel-supply-entries = <&dsi_panel_pwr_supply_urus>;
	qcom,mdss-dsi-no-panel-on-read-support;
	qcom,mdss-dsi-bl-pmic-control-type = "bl_ctrl_dcs";
	qcom,mdss-dsi-bl-min-level = <420>;
	qcom,mdss-dsi-bl-max-level = <16180>;
	qcom,mdss-dsi-bl-default-level = <7001>;
	qcom,mdss-brightness-max-level = <16180>;
	qcom,platform-reset-gpio = <&tlmm 146 0>;
	qcom,bl-dsc-cmd-state = "dsi_hs_mode";
	qcom,mdss-dsi-bl-inverted-dbv;
	qcom,mdss-dsi-bl-is-exponent;

	qcom,mdss-dsi-panel-status-check-mode = "reg_read";
	qcom,mdss-dsi-panel-status-command = [06 01 00 01 00 00 01 0a];
	qcom,mdss-dsi-panel-status-command-state = "dsi_lp_mode";
	qcom,mdss-dsi-panel-status-value = <0x9c>;
	qcom,mdss-dsi-panel-status-read-length = <1>;
	qcom,esd-check-enabled;
	qcom,cellid-read-enabled;
	qcom,mdss-dsi-panel-cellid-send-command-enabled;
	qcom,mdss-dsi-panel-cellid-send-command = [
		39 00 00 00 00 00 04 FF 5A A5 1D];
	qcom,mdss-dsi-panel-cellid-read-length = <23>;
	qcom,mdss-dsi-panel-cellid-offset = <0>;
	qcom,mdss-dsi-panel-cellid-command = [
		06 01 00 01 00 00 01 80];
	qcom,mdss-dsi-panel-cellid-send-back-command = [
		39 00 00 00 00 00 04 FF 5A A5 00];

	qcom,mdss-dsi-panel-hdr-enabled;
	qcom,mdss-dsi-panel-hdr-color-primaries = <15600 16450 34000
	        16000 13250 34500 7500 3000>;
	qcom,mdss-dsi-panel-peak-brightness = <15000000>;
	qcom,mdss-dsi-panel-blackness-level = <1>;

	qcom,mdss-dsi-hbm-off-command = [
		39 00 00 40 00 00 04 FF 5A A5 1E
		39 00 00 40 00 00 02 80 89
		39 00 00 40 00 00 04 FF 5A A5 00
		39 00 00 00 00 00 02 6E 00
	];
	qcom,mdss-dsi-hbm-off-command-state = "dsi_hs_mode";
	qcom,mdss-dsi-hbm-on-command = [
		39 00 00 40 00 00 04 FF 5A A5 1E
		39 00 00 40 00 00 02 80 A9
		39 00 00 40 00 00 02 85 08
		39 00 00 40 00 00 04 FF 5A A5 00
		39 00 00 00 00 00 03 51 3F FC
	];
	qcom,mdss-dsi-hbm-on-command-state = "dsi_hs_mode";

	qcom,apl-enabled;
	qcom,mdss-dsi-panel-APL-THRESHOLD-BL = <16000>;
	qcom,mdss-dsi-panel-APL-FUNC-ID = <0>;
	qcom,mdss-dsi-panel-apl-on-command = [
		39 00 00 40 00 00 04 FF 5A A5 1E
		39 00 00 40 00 00 02 80 A9
		39 00 00 40 00 00 02 85 08
		39 00 00 00 00 00 04 FF 5A A5 00];
	qcom,mdss-dsi-panel-apl-off-command = [
		39 00 00 40 00 00 04 FF 5A A5 1E
		39 00 00 40 00 00 02 80 89
		39 00 00 00 00 00 04 FF 5A A5 00];

	//qcom,ulps-enabled;
	qcom,mdss-dsi-display-timings {
		timing@0 { //120
			qcom,framerate-group-no-duplicated;
			qcom,framerate-group-120hz-based;
			qcom,mdss-dsi-panel-clockrate = <1234000000>;
			qcom,display-topology = <2 2 1>;
			qcom,default-topology-index = <0>;
			qcom,mdss-dsi-panel-phy-timings = [00 29 0A 0B 1B 1A 0A
							0B 0A 02 04 00 21 10];
		};
		timing@1 { //144
			qcom,framerate-group-no-duplicated;
			qcom,mdss-dsi-panel-clockrate = <1480000000>;
			qcom,display-topology = <2 2 1>;
			qcom,default-topology-index = <0>;
			qcom,mdss-dsi-panel-phy-timings = [00 2F 0D 0D 1E 1C 0C
							0D 0C 02 04 00 27 11];
		};
		timing@2 { //90
			qcom,framerate-group-no-duplicated;
			qcom,framerate-group-90hz-based;
			qcom,mdss-dsi-panel-clockrate = <1234000000>;
			qcom,display-topology = <2 2 1>;
			qcom,default-topology-index = <0>;
			qcom,mdss-dsi-panel-phy-timings = [00 29 0A 0B 1B 1A 0A
							0B 0A 02 04 00 21 10];
		};
		timing@3 { //60
			qcom,framerate-group-no-duplicated;
			qcom,framerate-group-120hz-based;
			qcom,mdss-dsi-panel-clockrate = <1234000000>;
			qcom,display-topology = <2 2 1>;
			qcom,default-topology-index = <0>;
			qcom,mdss-dsi-panel-phy-timings = [00 29 0A 0B 1B 1A 0A
							0B 0A 02 04 00 21 10];
		};
		timing@4 { //30
			qcom,framerate-group-no-duplicated;
			qcom,framerate-group-120hz-based;
			qcom,mdss-dsi-panel-clockrate = <1234000000>;
			qcom,display-topology = <2 2 1>;
			qcom,default-topology-index = <0>;
			qcom,mdss-dsi-panel-phy-timings = [00 29 0A 0B 1B 1A 0A
							0B 0A 02 04 00 21 10];
		};
		timing@5 { //24
			qcom,framerate-group-no-duplicated;
			qcom,framerate-group-120hz-based;
			qcom,mdss-dsi-panel-clockrate = <1234000000>;
			qcom,display-topology = <2 2 1>;
			qcom,default-topology-index = <0>;
			qcom,mdss-dsi-panel-phy-timings = [00 29 0A 0B 1B 1A 0A
							0B 0A 02 04 00 21 10];
		};
		timing@6 { //10
			qcom,framerate-group-special-idle-10hz;
			qcom,mdss-dsi-panel-clockrate = <1234000000>;
			qcom,display-topology = <2 2 1>;
			qcom,default-topology-index = <0>;
			qcom,mdss-dsi-panel-phy-timings = [00 29 0A 0B 1B 1A 0A
							0B 0A 02 04 00 21 10];
		};
		timing@7 { //1
			qcom,framerate-group-special-idle-1hz;
			qcom,mdss-dsi-panel-clockrate = <1234000000>;
			qcom,display-topology = <2 2 1>;
			qcom,default-topology-index = <0>;
			qcom,mdss-dsi-panel-phy-timings = [00 29 0A 0B 1B 1A 0A
							0B 0A 02 04 00 21 10];
		};
		timing@8 { //1080p 120hz
			qcom,framerate-group-no-duplicated;
			qcom,framerate-group-120hz-based;
			qcom,mdss-dsi-panel-clockrate = <720000000>;
			qcom,display-topology = <2 2 1>;
			qcom,default-topology-index = <0>;
			qcom,mdss-dsi-panel-phy-timings = [00 19 06 06 15 14 07
							06 07 02 04 00 16 0B];
		};
		timing@9 { //1080p 144hz
			qcom,framerate-group-no-duplicated;
			qcom,mdss-dsi-panel-clockrate = <864000000>;
			qcom,display-topology = <2 2 1>;
			qcom,default-topology-index = <0>;
			qcom,mdss-dsi-panel-phy-timings = [00 1D 08 07 17 16 07
							07 08 02 04 00 19 0C];
		};
		timing@10 { //1080p 90hz
			qcom,framerate-group-no-duplicated;
			qcom,framerate-group-90hz-based;
			qcom,mdss-dsi-panel-clockrate = <720000000>;
			qcom,display-topology = <2 2 1>;
			qcom,default-topology-index = <0>;
			qcom,mdss-dsi-panel-phy-timings = [00 19 06 06 15 14 07
							06 07 02 04 00 16 0B];
		};
		timing@11 { //1080p 60hz
			qcom,framerate-group-no-duplicated;
			qcom,framerate-group-120hz-based;
			qcom,mdss-dsi-panel-clockrate = <720000000>;
			qcom,display-topology = <2 2 1>;
			qcom,default-topology-index = <0>;
			qcom,mdss-dsi-panel-phy-timings = [00 19 06 06 15 14 07
							06 07 02 04 00 16 0B];
		};
		timing@12 { //1080p 30hz
			qcom,framerate-group-no-duplicated;
			qcom,framerate-group-120hz-based;
			qcom,mdss-dsi-panel-clockrate = <720000000>;
			qcom,display-topology = <2 2 1>;
			qcom,default-topology-index = <0>;
			qcom,mdss-dsi-panel-phy-timings = [00 19 06 06 15 14 07
							06 07 02 04 00 16 0B];
		};
		timing@13 { //1080p 24hz
			qcom,framerate-group-no-duplicated;
			qcom,framerate-group-120hz-based;
			qcom,mdss-dsi-panel-clockrate = <720000000>;
			qcom,display-topology = <2 2 1>;
			qcom,default-topology-index = <0>;
			qcom,mdss-dsi-panel-phy-timings = [00 19 06 06 15 14 07
							06 07 02 04 00 16 0B];
		};
		timing@14 { //1080p 10hz
			qcom,framerate-group-special-idle-10hz;
			qcom,mdss-dsi-panel-clockrate = <720000000>;
			qcom,display-topology = <2 2 1>;
			qcom,default-topology-index = <0>;
			qcom,mdss-dsi-panel-phy-timings = [00 19 06 06 15 14 07
							06 07 02 04 00 16 0B];
		};
		timing@15 { //1080p 1hz
			qcom,framerate-group-special-idle-1hz;
			qcom,mdss-dsi-panel-clockrate = <720000000>;
			qcom,display-topology = <2 2 1>;
			qcom,default-topology-index = <0>;
			qcom,mdss-dsi-panel-phy-timings = [00 19 06 06 15 14 07
							06 07 02 04 00 16 0B];
		};
	};
};

&mot_boe_ili97701A_682_1440x3168_dsc_cmd_v3 {
	qcom,dsi-select-clocks = "pll_byte_clk1", "pll_dsi_clk1";
	qcom,dsi-ctrl-num = <1>;
	qcom,dsi-phy-num = <1>;
	qcom,panel-supply-entries = <&dsi_panel_pwr_supply_urus>;
	qcom,mdss-dsi-no-panel-on-read-support;
	qcom,mdss-dsi-bl-pmic-control-type = "bl_ctrl_dcs";
	qcom,mdss-dsi-bl-min-level = <420>;
	qcom,mdss-dsi-bl-max-level = <16180>;
	qcom,mdss-dsi-bl-default-level = <7001>;
	qcom,mdss-brightness-max-level = <16180>;
	qcom,platform-reset-gpio = <&tlmm 146 0>;
	qcom,bl-dsc-cmd-state = "dsi_hs_mode";
	qcom,mdss-dsi-bl-inverted-dbv;
	qcom,mdss-dsi-bl-is-exponent;

	qcom,mdss-dsi-panel-status-check-mode = "reg_read";
	qcom,mdss-dsi-panel-status-command = [06 01 00 01 00 00 01 0a];
	qcom,mdss-dsi-panel-status-command-state = "dsi_lp_mode";
	qcom,mdss-dsi-panel-status-value = <0x9c>;
	qcom,mdss-dsi-panel-status-read-length = <1>;
	qcom,esd-check-enabled;
	qcom,cellid-read-enabled;
	qcom,mdss-dsi-panel-cellid-send-command-enabled;
	qcom,mdss-dsi-panel-cellid-send-command = [
		39 00 00 00 00 00 04 FF 5A A5 1D];
	qcom,mdss-dsi-panel-cellid-read-length = <23>;
	qcom,mdss-dsi-panel-cellid-offset = <0>;
	qcom,mdss-dsi-panel-cellid-command = [
		06 01 00 01 00 00 01 80];
	qcom,mdss-dsi-panel-cellid-send-back-command = [
		39 00 00 00 00 00 04 FF 5A A5 00];

	qcom,mdss-dsi-panel-hdr-enabled;
	qcom,mdss-dsi-panel-hdr-color-primaries = <15600 16450 34000
	        16000 13250 34500 7500 3000>;
	qcom,mdss-dsi-panel-peak-brightness = <15000000>;
	qcom,mdss-dsi-panel-blackness-level = <1>;

	qcom,mdss-dsi-hbm-off-command = [
		39 00 00 40 00 00 04 FF 5A A5 1E
		39 00 00 40 00 00 02 80 89
		39 00 00 40 00 00 04 FF 5A A5 00
		39 00 00 00 00 00 02 6E 00
	];
	qcom,mdss-dsi-hbm-off-command-state = "dsi_hs_mode";
	qcom,mdss-dsi-hbm-on-command = [
		39 00 00 40 00 00 04 FF 5A A5 1E
		39 00 00 40 00 00 02 80 A9
		39 00 00 40 00 00 02 85 08
		39 00 00 40 00 00 04 FF 5A A5 00
		39 00 00 00 00 00 03 51 3F FC
	];
	qcom,mdss-dsi-hbm-on-command-state = "dsi_hs_mode";

	qcom,apl-enabled;
	qcom,mdss-dsi-panel-APL-THRESHOLD-BL = <16000>;
	qcom,mdss-dsi-panel-APL-FUNC-ID = <0>;
	qcom,mdss-dsi-panel-apl-on-command = [
		39 00 00 40 00 00 04 FF 5A A5 1E
		39 00 00 40 00 00 02 80 A9
		39 00 00 40 00 00 02 85 08
		39 00 00 00 00 00 04 FF 5A A5 00];
	qcom,mdss-dsi-panel-apl-off-command = [
		39 00 00 40 00 00 04 FF 5A A5 1E
		39 00 00 40 00 00 02 80 89
		39 00 00 00 00 00 04 FF 5A A5 00];

	//qcom,ulps-enabled;
	qcom,mdss-dsi-display-timings {
		timing@0 { //120
			qcom,framerate-group-no-duplicated;
			qcom,framerate-group-120hz-based;
			qcom,mdss-dsi-panel-clockrate = <1234000000>;
			qcom,display-topology = <2 2 1>;
			qcom,default-topology-index = <0>;
			qcom,mdss-dsi-panel-phy-timings = [00 29 0A 0B 1B 1A 0A
							0B 0A 02 04 00 21 10];
		};
		timing@1 { //144
			qcom,framerate-group-no-duplicated;
			qcom,mdss-dsi-panel-clockrate = <1480000000>;
			qcom,display-topology = <2 2 1>;
			qcom,default-topology-index = <0>;
			qcom,mdss-dsi-panel-phy-timings = [00 2F 0D 0D 1E 1C 0C
							0D 0C 02 04 00 27 11];
		};
		timing@2 { //90
			qcom,framerate-group-no-duplicated;
			qcom,framerate-group-90hz-based;
			qcom,mdss-dsi-panel-clockrate = <1234000000>;
			qcom,display-topology = <2 2 1>;
			qcom,default-topology-index = <0>;
			qcom,mdss-dsi-panel-phy-timings = [00 29 0A 0B 1B 1A 0A
							0B 0A 02 04 00 21 10];
		};
		timing@3 { //60
			qcom,framerate-group-no-duplicated;
			qcom,framerate-group-120hz-based;
			qcom,mdss-dsi-panel-clockrate = <1234000000>;
			qcom,display-topology = <2 2 1>;
			qcom,default-topology-index = <0>;
			qcom,mdss-dsi-panel-phy-timings = [00 29 0A 0B 1B 1A 0A
							0B 0A 02 04 00 21 10];
		};
		timing@4 { //30
			qcom,framerate-group-no-duplicated;
			qcom,framerate-group-120hz-based;
			qcom,mdss-dsi-panel-clockrate = <1234000000>;
			qcom,display-topology = <2 2 1>;
			qcom,default-topology-index = <0>;
			qcom,mdss-dsi-panel-phy-timings = [00 29 0A 0B 1B 1A 0A
							0B 0A 02 04 00 21 10];
		};
		timing@5 { //24
			qcom,framerate-group-no-duplicated;
			qcom,framerate-group-120hz-based;
			qcom,mdss-dsi-panel-clockrate = <1234000000>;
			qcom,display-topology = <2 2 1>;
			qcom,default-topology-index = <0>;
			qcom,mdss-dsi-panel-phy-timings = [00 29 0A 0B 1B 1A 0A
							0B 0A 02 04 00 21 10];
		};
		timing@6 { //10
			qcom,framerate-group-special-idle-10hz;
			qcom,mdss-dsi-panel-clockrate = <1234000000>;
			qcom,display-topology = <2 2 1>;
			qcom,default-topology-index = <0>;
			qcom,mdss-dsi-panel-phy-timings = [00 29 0A 0B 1B 1A 0A
							0B 0A 02 04 00 21 10];
		};
		timing@7 { //1
			qcom,framerate-group-special-idle-1hz;
			qcom,mdss-dsi-panel-clockrate = <1234000000>;
			qcom,display-topology = <2 2 1>;
			qcom,default-topology-index = <0>;
			qcom,mdss-dsi-panel-phy-timings = [00 29 0A 0B 1B 1A 0A
							0B 0A 02 04 00 21 10];
		};
		timing@8 { //1080p 120hz
			qcom,framerate-group-no-duplicated;
			qcom,framerate-group-120hz-based;
			qcom,mdss-dsi-panel-clockrate = <720000000>;
			qcom,display-topology = <2 2 1>;
			qcom,default-topology-index = <0>;
			qcom,mdss-dsi-panel-phy-timings = [00 19 06 06 15 14 07
							06 07 02 04 00 16 0B];
		};
		timing@9 { //1080p 144hz
			qcom,framerate-group-no-duplicated;
			qcom,mdss-dsi-panel-clockrate = <864000000>;
			qcom,display-topology = <2 2 1>;
			qcom,default-topology-index = <0>;
			qcom,mdss-dsi-panel-phy-timings = [00 1D 08 07 17 16 07
							07 08 02 04 00 19 0C];
		};
		timing@10 { //1080p 90hz
			qcom,framerate-group-no-duplicated;
			qcom,framerate-group-90hz-based;
			qcom,mdss-dsi-panel-clockrate = <720000000>;
			qcom,display-topology = <2 2 1>;
			qcom,default-topology-index = <0>;
			qcom,mdss-dsi-panel-phy-timings = [00 19 06 06 15 14 07
							06 07 02 04 00 16 0B];
		};
		timing@11 { //1080p 60hz
			qcom,framerate-group-no-duplicated;
			qcom,framerate-group-120hz-based;
			qcom,mdss-dsi-panel-clockrate = <720000000>;
			qcom,display-topology = <2 2 1>;
			qcom,default-topology-index = <0>;
			qcom,mdss-dsi-panel-phy-timings = [00 19 06 06 15 14 07
							06 07 02 04 00 16 0B];
		};
		timing@12 { //1080p 30hz
			qcom,framerate-group-no-duplicated;
			qcom,framerate-group-120hz-based;
			qcom,mdss-dsi-panel-clockrate = <720000000>;
			qcom,display-topology = <2 2 1>;
			qcom,default-topology-index = <0>;
			qcom,mdss-dsi-panel-phy-timings = [00 19 06 06 15 14 07
							06 07 02 04 00 16 0B];
		};
		timing@13 { //1080p 24hz
			qcom,framerate-group-no-duplicated;
			qcom,framerate-group-120hz-based;
			qcom,mdss-dsi-panel-clockrate = <720000000>;
			qcom,display-topology = <2 2 1>;
			qcom,default-topology-index = <0>;
			qcom,mdss-dsi-panel-phy-timings = [00 19 06 06 15 14 07
							06 07 02 04 00 16 0B];
		};
		timing@14 { //1080p 10hz
			qcom,framerate-group-special-idle-10hz;
			qcom,mdss-dsi-panel-clockrate = <720000000>;
			qcom,display-topology = <2 2 1>;
			qcom,default-topology-index = <0>;
			qcom,mdss-dsi-panel-phy-timings = [00 19 06 06 15 14 07
							06 07 02 04 00 16 0B];
		};
		timing@15 { //1080p 1hz
			qcom,framerate-group-special-idle-1hz;
			qcom,mdss-dsi-panel-clockrate = <720000000>;
			qcom,display-topology = <2 2 1>;
			qcom,default-topology-index = <0>;
			qcom,mdss-dsi-panel-phy-timings = [00 19 06 06 15 14 07
							06 07 02 04 00 16 0B];
		};
	};
};

&mot_boe_ili97701A_682_1440x3168_dsc_cmd_v4 {
	qcom,dsi-select-clocks = "pll_byte_clk1", "pll_dsi_clk1";
	qcom,dsi-ctrl-num = <1>;
	qcom,dsi-phy-num = <1>;
	qcom,panel-supply-entries = <&dsi_panel_pwr_supply_urus>;
	qcom,mdss-dsi-no-panel-on-read-support;
	qcom,mdss-dsi-bl-pmic-control-type = "bl_ctrl_dcs";
	qcom,mdss-dsi-bl-min-level = <420>;
	qcom,mdss-dsi-bl-max-level = <16180>;
	qcom,mdss-dsi-bl-default-level = <7001>;
	qcom,mdss-brightness-max-level = <16180>;
	qcom,platform-reset-gpio = <&tlmm 146 0>;
	qcom,bl-dsc-cmd-state = "dsi_hs_mode";
	qcom,mdss-dsi-bl-inverted-dbv;
	qcom,mdss-dsi-bl-is-exponent;

	qcom,mdss-dsi-panel-status-check-mode = "reg_read";
	qcom,mdss-dsi-panel-status-command = [06 01 00 01 00 00 01 0a];
	qcom,mdss-dsi-panel-status-command-state = "dsi_lp_mode";
	qcom,mdss-dsi-panel-status-value = <0x9c>;
	qcom,mdss-dsi-panel-status-read-length = <1>;
	qcom,esd-check-enabled;
	qcom,cellid-read-enabled;
	qcom,mdss-dsi-panel-cellid-send-command-enabled;
	qcom,mdss-dsi-panel-cellid-send-command = [
		39 00 00 00 00 00 04 FF 5A A5 1D];
	qcom,mdss-dsi-panel-cellid-read-length = <23>;
	qcom,mdss-dsi-panel-cellid-offset = <0>;
	qcom,mdss-dsi-panel-cellid-command = [
		06 01 00 01 00 00 01 80];
	qcom,mdss-dsi-panel-cellid-send-back-command = [
		39 00 00 00 00 00 04 FF 5A A5 00];

	qcom,mdss-dsi-panel-hdr-enabled;
	qcom,mdss-dsi-panel-hdr-color-primaries = <15600 16450 34000
	        16000 13250 34500 7500 3000>;
	qcom,mdss-dsi-panel-peak-brightness = <15000000>;
	qcom,mdss-dsi-panel-blackness-level = <1>;

	qcom,mdss-dsi-hbm-off-command = [
		39 00 00 40 00 00 04 FF 5A A5 1E
		39 00 00 40 00 00 02 80 89
		39 00 00 40 00 00 04 FF 5A A5 00
		39 00 00 00 00 00 02 6E 00
	];
	qcom,mdss-dsi-hbm-off-command-state = "dsi_hs_mode";
	qcom,mdss-dsi-hbm-on-command = [
		39 00 00 40 00 00 04 FF 5A A5 1E
		39 00 00 40 00 00 02 80 A9
		39 00 00 40 00 00 02 85 08
		39 00 00 40 00 00 04 FF 5A A5 00
		39 00 00 00 00 00 03 51 3F FC
	];
	qcom,mdss-dsi-hbm-on-command-state = "dsi_hs_mode";

	qcom,apl-enabled;
	qcom,mdss-dsi-panel-APL-THRESHOLD-BL = <16000>;
	qcom,mdss-dsi-panel-APL-FUNC-ID = <0>;
	qcom,mdss-dsi-panel-apl-on-command = [
		39 00 00 40 00 00 04 FF 5A A5 1E
		39 00 00 40 00 00 02 80 A9
		39 00 00 40 00 00 02 85 08
		39 00 00 00 00 00 04 FF 5A A5 00];
	qcom,mdss-dsi-panel-apl-off-command = [
		39 00 00 40 00 00 04 FF 5A A5 1E
		39 00 00 40 00 00 02 80 89
		39 00 00 00 00 00 04 FF 5A A5 00];

	//qcom,ulps-enabled;
	qcom,mdss-dsi-display-timings {
		timing@0 { //120
			qcom,framerate-group-no-duplicated;
			qcom,framerate-group-120hz-based;
			qcom,mdss-dsi-panel-clockrate = <1234000000>;
			qcom,display-topology = <2 2 1>;
			qcom,default-topology-index = <0>;
			qcom,mdss-dsi-panel-phy-timings = [00 29 0A 0B 1B 1A 0A
							0B 0A 02 04 00 21 10];
		};
		timing@1 { //144
			qcom,framerate-group-no-duplicated;
			qcom,mdss-dsi-panel-clockrate = <1480000000>;
			qcom,display-topology = <2 2 1>;
			qcom,default-topology-index = <0>;
			qcom,mdss-dsi-panel-phy-timings = [00 2F 0D 0D 1E 1C 0C
							0D 0C 02 04 00 27 11];
		};
		timing@2 { //90
			qcom,framerate-group-no-duplicated;
			qcom,framerate-group-90hz-based;
			qcom,mdss-dsi-panel-clockrate = <1234000000>;
			qcom,display-topology = <2 2 1>;
			qcom,default-topology-index = <0>;
			qcom,mdss-dsi-panel-phy-timings = [00 29 0A 0B 1B 1A 0A
							0B 0A 02 04 00 21 10];
		};
		timing@3 { //60
			qcom,framerate-group-no-duplicated;
			qcom,framerate-group-120hz-based;
			qcom,mdss-dsi-panel-clockrate = <1234000000>;
			qcom,display-topology = <2 2 1>;
			qcom,default-topology-index = <0>;
			qcom,mdss-dsi-panel-phy-timings = [00 29 0A 0B 1B 1A 0A
							0B 0A 02 04 00 21 10];
		};
		timing@4 { //30
			qcom,framerate-group-no-duplicated;
			qcom,framerate-group-120hz-based;
			qcom,mdss-dsi-panel-clockrate = <1234000000>;
			qcom,display-topology = <2 2 1>;
			qcom,default-topology-index = <0>;
			qcom,mdss-dsi-panel-phy-timings = [00 29 0A 0B 1B 1A 0A
							0B 0A 02 04 00 21 10];
		};
		timing@5 { //24
			qcom,framerate-group-no-duplicated;
			qcom,framerate-group-120hz-based;
			qcom,mdss-dsi-panel-clockrate = <1234000000>;
			qcom,display-topology = <2 2 1>;
			qcom,default-topology-index = <0>;
			qcom,mdss-dsi-panel-phy-timings = [00 29 0A 0B 1B 1A 0A
							0B 0A 02 04 00 21 10];
		};
		timing@6 { //10
			qcom,framerate-group-special-idle-10hz;
			qcom,mdss-dsi-panel-clockrate = <1234000000>;
			qcom,display-topology = <2 2 1>;
			qcom,default-topology-index = <0>;
			qcom,mdss-dsi-panel-phy-timings = [00 29 0A 0B 1B 1A 0A
							0B 0A 02 04 00 21 10];
		};
		timing@7 { //1
			qcom,framerate-group-special-idle-1hz;
			qcom,mdss-dsi-panel-clockrate = <1234000000>;
			qcom,display-topology = <2 2 1>;
			qcom,default-topology-index = <0>;
			qcom,mdss-dsi-panel-phy-timings = [00 29 0A 0B 1B 1A 0A
							0B 0A 02 04 00 21 10];
		};
		timing@8 { //1080p 120hz
			qcom,framerate-group-no-duplicated;
			qcom,framerate-group-120hz-based;
			qcom,mdss-dsi-panel-clockrate = <720000000>;
			qcom,display-topology = <2 2 1>;
			qcom,default-topology-index = <0>;
			qcom,mdss-dsi-panel-phy-timings = [00 19 06 06 15 14 07
							06 07 02 04 00 16 0B];
		};
		timing@9 { //1080p 144hz
			qcom,framerate-group-no-duplicated;
			qcom,mdss-dsi-panel-clockrate = <864000000>;
			qcom,display-topology = <2 2 1>;
			qcom,default-topology-index = <0>;
			qcom,mdss-dsi-panel-phy-timings = [00 1D 08 07 17 16 07
							07 08 02 04 00 19 0C];
		};
		timing@10 { //1080p 90hz
			qcom,framerate-group-no-duplicated;
			qcom,framerate-group-90hz-based;
			qcom,mdss-dsi-panel-clockrate = <720000000>;
			qcom,display-topology = <2 2 1>;
			qcom,default-topology-index = <0>;
			qcom,mdss-dsi-panel-phy-timings = [00 19 06 06 15 14 07
							06 07 02 04 00 16 0B];
		};
		timing@11 { //1080p 60hz
			qcom,framerate-group-no-duplicated;
			qcom,framerate-group-120hz-based;
			qcom,mdss-dsi-panel-clockrate = <720000000>;
			qcom,display-topology = <2 2 1>;
			qcom,default-topology-index = <0>;
			qcom,mdss-dsi-panel-phy-timings = [00 19 06 06 15 14 07
							06 07 02 04 00 16 0B];
		};
		timing@12 { //1080p 30hz
			qcom,framerate-group-no-duplicated;
			qcom,framerate-group-120hz-based;
			qcom,mdss-dsi-panel-clockrate = <720000000>;
			qcom,display-topology = <2 2 1>;
			qcom,default-topology-index = <0>;
			qcom,mdss-dsi-panel-phy-timings = [00 19 06 06 15 14 07
							06 07 02 04 00 16 0B];
		};
		timing@13 { //1080p 24hz
			qcom,framerate-group-no-duplicated;
			qcom,framerate-group-120hz-based;
			qcom,mdss-dsi-panel-clockrate = <720000000>;
			qcom,display-topology = <2 2 1>;
			qcom,default-topology-index = <0>;
			qcom,mdss-dsi-panel-phy-timings = [00 19 06 06 15 14 07
							06 07 02 04 00 16 0B];
		};
		timing@14 { //1080p 10hz
			qcom,framerate-group-special-idle-10hz;
			qcom,mdss-dsi-panel-clockrate = <720000000>;
			qcom,display-topology = <2 2 1>;
			qcom,default-topology-index = <0>;
			qcom,mdss-dsi-panel-phy-timings = [00 19 06 06 15 14 07
							06 07 02 04 00 16 0B];
		};
		timing@15 { //1080p 1hz
			qcom,framerate-group-special-idle-1hz;
			qcom,mdss-dsi-panel-clockrate = <720000000>;
			qcom,display-topology = <2 2 1>;
			qcom,default-topology-index = <0>;
			qcom,mdss-dsi-panel-phy-timings = [00 19 06 06 15 14 07
							06 07 02 04 00 16 0B];
		};
	};
};

&mot_dummy_vid_qhd {
       qcom,mdss-dsi-display-timings {
                timing@0{
                       qcom,mdss-dsi-panel-width = <1080>;
                       qcom,mdss-dsi-panel-height = <2400>;
               };
       };
};

&mot_dummy_vid_qhd {
	qcom,dsi-select-clocks = "pll_byte_clk1", "pll_dsi_clk1";
	qcom,dsi-ctrl-num = <1>;
	qcom,dsi-phy-num = <1>;
	qcom,platform-reset-gpio = <&tlmm 146 0>;
	qcom,mdss-dsi-display-timings {
		timing@0 {
			qcom,display-topology = <1 0 1>;
			qcom,default-topology-index = <0>;
		};
	};
};

&sde_dsi {
	qcom,dsi-default-panel = <&mot_dummy_vid_qhd>;
};

&qupv3_se4_spi {
	goodix-berlin@0 {
		panel = <&mot_boe_ili97680A_678_1264x2780_dsc_cmd_v1
		         &mot_boe_ili97680A_678_1264x2780_dsc_cmd_v2
		         &mot_boe_ili97680A_678_1264x2780_dsc_cmd_v3
		         &mot_boe_ili97680A_678_1264x2780_dsc_cmd_v4
		         &mot_boe_ili97701A_682_1440x3168_dsc_cmd_v0
		         &mot_boe_ili97701A_682_1440x3168_dsc_cmd_v1
		         &mot_boe_ili97701A_682_1440x3168_dsc_cmd_v2
		         &mot_boe_ili97701A_682_1440x3168_dsc_cmd_v3
		         &mot_boe_ili97701A_682_1440x3168_dsc_cmd_v4>;
	};
};

&battery_charger {
        qcom,display-panels = <&mot_boe_ili97680A_678_1264x2780_dsc_cmd_v1
                               &mot_boe_ili97680A_678_1264x2780_dsc_cmd_v2
                               &mot_boe_ili97680A_678_1264x2780_dsc_cmd_v3
                               &mot_boe_ili97680A_678_1264x2780_dsc_cmd_v4
                               &mot_boe_ili97701A_682_1440x3168_dsc_cmd_v0
                               &mot_boe_ili97701A_682_1440x3168_dsc_cmd_v1
                               &mot_boe_ili97701A_682_1440x3168_dsc_cmd_v2
                               &mot_boe_ili97701A_682_1440x3168_dsc_cmd_v3
		               &mot_boe_ili97701A_682_1440x3168_dsc_cmd_v4>;

};
